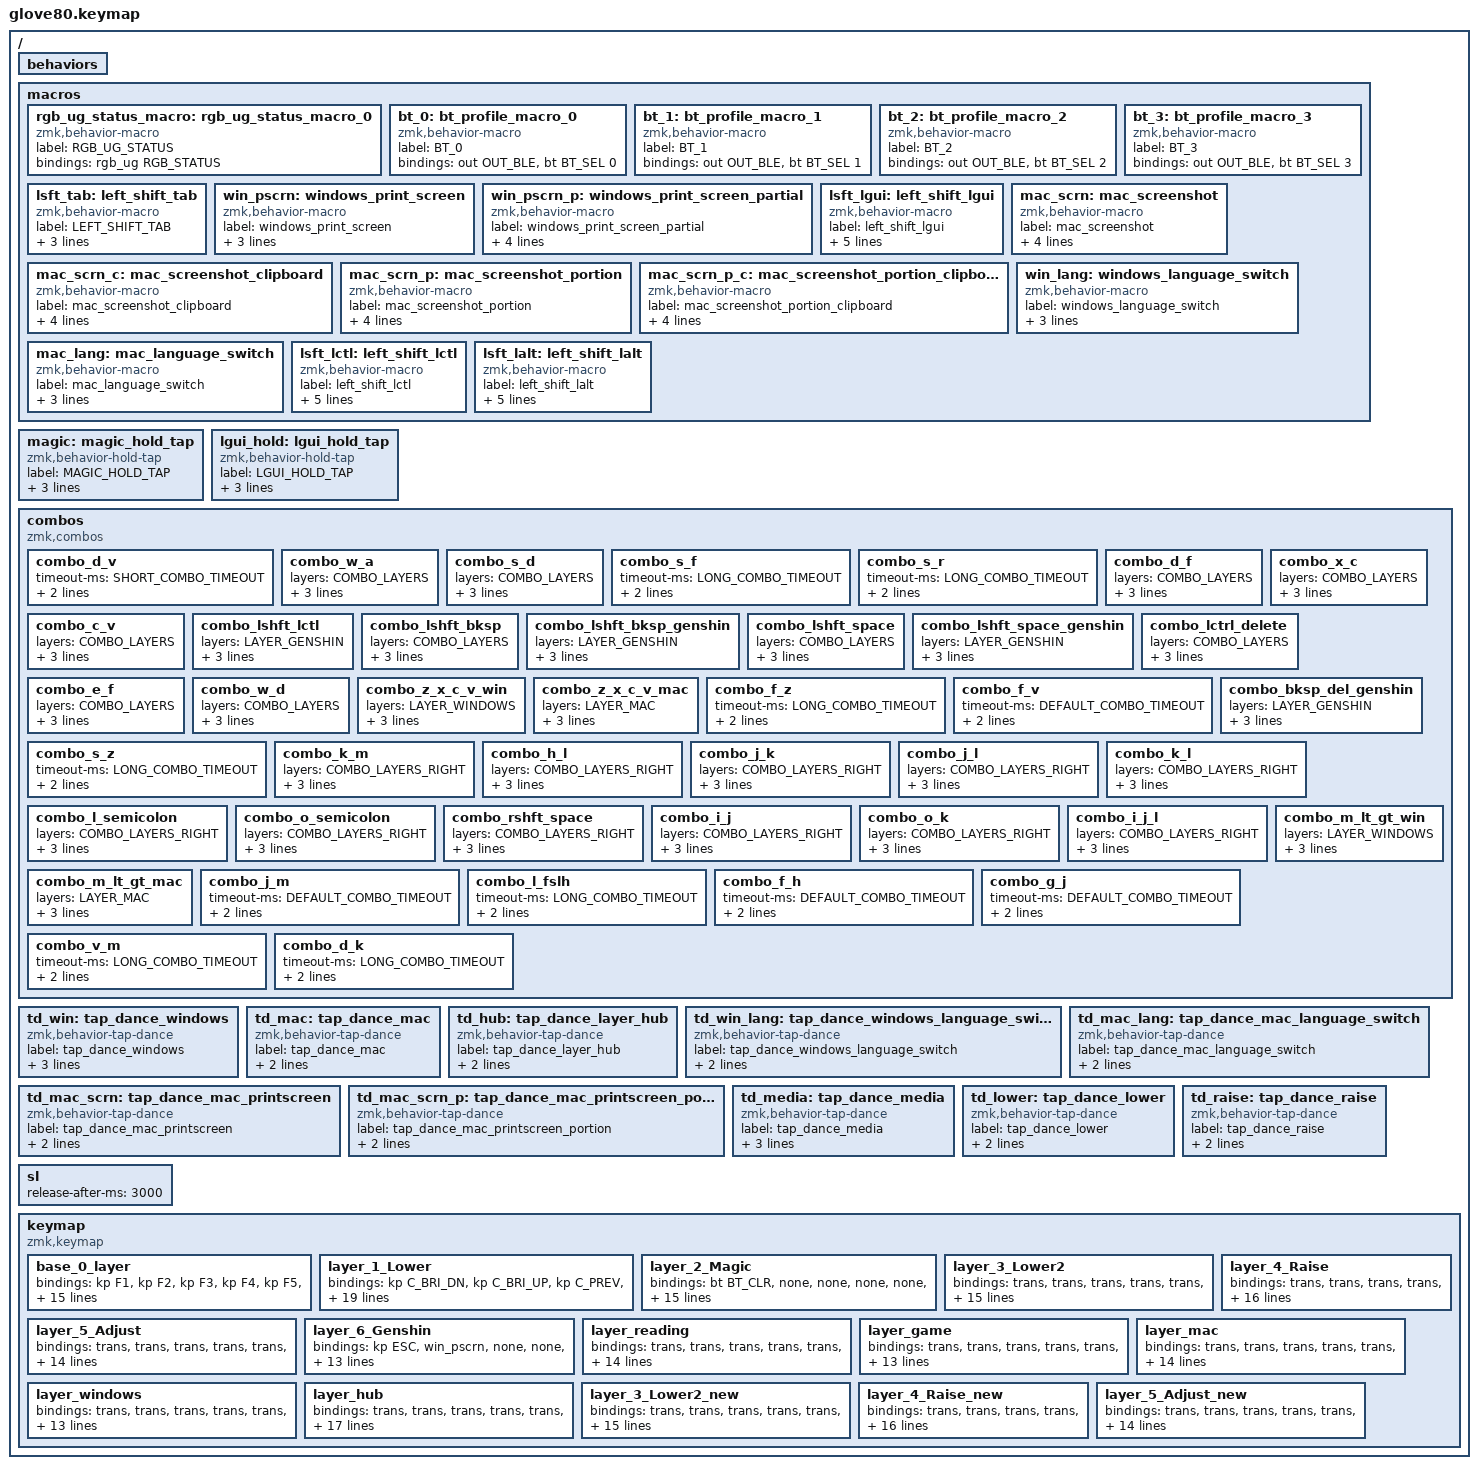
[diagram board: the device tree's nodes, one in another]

/*
 * Copyright (c) 2020 The ZMK Contributors
 * Copyright (c) 2022 Innaworks Development Limited, trading as MoErgo
 *
 * SPDX-License-Identifier: MIT
 */


/* THIS FILE WAS GENERATED BY GLOVE80 LAYOUT EDITOR
 *
 * This file was generated automatically. You may or may not want to
 * edit it directly.
 */

#include <behaviors.dtsi>
/* include all behaviour includes needed by system behaviors/macros */
#include <dt-bindings/zmk/outputs.h>

/* Include behaviour includes needed by key binds - automatically generated */
#include <dt-bindings/zmk/keys.h>
#include <dt-bindings/zmk/bt.h>
#include <dt-bindings/zmk/rgb.h>
#include <dt-bindings/zmk/outputs.h>

#define LAYER_DEFAULT 0
#define LAYER_LOWER_OLD 1
#define LAYER_MAGIC 2
//#define LAYER_LOWER 3
//#define LAYER_RAISE 4
//#define LAYER_ADJUST 5
#define LAYER_GENSHIN 6
#define LAYER_READING 7
#define LAYER_GAME 8
#define LAYER_MAC 9
#define LAYER_WINDOWS 10
#define LAYER_HUB 11
#define LAYER_LOWER 12
#define LAYER_RAISE 13
#define LAYER_ADJUST 14

#define COMBO_LAYERS LAYER_DEFAULT LAYER_READING LAYER_MAC LAYER_WINDOWS
#define COMBO_LAYERS_RIGHT COMBO_LAYERS LAYER_GENSHIN

#define MO_LOWER &mo LAYER_LOWER
#define MO_RAISE &mo LAYER_RAISE
#define MO_ADJUST &mo LAYER_ADJUST
#define MO_GENSHIN &mo LAYER_GENSHIN

#define TG_GENSHIN &tog LAYER_GENSHIN
#define TG_READING &tog LAYER_READING
#define TG_GAME &tog LAYER_GAME

#define TO_DEFAULT &to LAYER_DEFAULT
#define TO_GENSHIN &to LAYER_GENSHIN
#define TO_READING &to LAYER_READING
#define TO_GAME &to LAYER_GAME

#define MAGIC_DEFAULT &magic LAYER_MAGIC LAYER_DEFAULT 

#define SHORT_COMBO_TIMEOUT 10
#define DEFAULT_COMBO_TIMEOUT 30
#define LONG_COMBO_TIMEOUT 50

#define TAP_DANCE_TERM_SHORT 100
#define TAP_DANCE_TERM_DEFAULT 300
#define TAP_DANCE_TERM_LONG 400

/ {
    /* Glove80 system behavior & macros */
    behaviors {
        // For the "layer" key, it'd nice to be able to use it as either a shift or a toggle.
        // Configure it as a tap dance, so the first tap (or hold) is a &mo and the second tap is a &to
    };

    macros {
        rgb_ug_status_macro: rgb_ug_status_macro_0 {
            label = "RGB_UG_STATUS";
            compatible = "zmk,behavior-macro";
            #binding-cells = <0>;
            bindings
                = <&rgb_ug RGB_STATUS>;
        };
        bt_0: bt_profile_macro_0 {
            label = "BT_0";
            compatible = "zmk,behavior-macro";
            #binding-cells = <0>;
            bindings
                = <&out OUT_BLE>,
                  <&bt BT_SEL 0>;
        };
        bt_1: bt_profile_macro_1 {
            label = "BT_1";
            compatible = "zmk,behavior-macro";
            #binding-cells = <0>;
            bindings
                = <&out OUT_BLE>,
                  <&bt BT_SEL 1>;
        };
        bt_2: bt_profile_macro_2 {
            label = "BT_2";
            compatible = "zmk,behavior-macro";
            #binding-cells = <0>;
            bindings
                = <&out OUT_BLE>,
                  <&bt BT_SEL 2>;
        };
        bt_3: bt_profile_macro_3 {
            label = "BT_3";
            compatible = "zmk,behavior-macro";
            #binding-cells = <0>;
            bindings
                = <&out OUT_BLE>,
                  <&bt BT_SEL 3>;
        };
    };

    magic: magic_hold_tap {
        compatible = "zmk,behavior-hold-tap";
        label = "MAGIC_HOLD_TAP";
        #binding-cells = <2>;
        flavor = "tap-preferred";
        tapping-term-ms = <200>;
        bindings = <&mo>, <&rgb_ug_status_macro>;
    }; 

    // TODO: work on how to get this going
    lgui_hold: lgui_hold_tap {
        compatible = "zmk,behavior-hold-tap";
        label = "LGUI_HOLD_TAP";
        #binding-cells = <2>;
        flavor = "balanced";
        tapping-term-ms = <0>;
        bindings = <&none>, <&kp>;
    }; 

    /* Main Layer Combos */
    combos {
        compatible = "zmk,combos";

        /* left hand */
        combo_d_v {
            timeout-ms = <SHORT_COMBO_TIMEOUT>;
            key-positions = <37 50>;
            bindings = <&td_lower>;
        };
        combo_w_a {
            layers = <COMBO_LAYERS>;
            timeout-ms = <LONG_COMBO_TIMEOUT>;
            key-positions = <24 35>;
            bindings = <&kp ESC>;
        };
        combo_s_d {
            layers = <COMBO_LAYERS>;
            timeout-ms = <LONG_COMBO_TIMEOUT>;
            key-positions = <36 37>;
            bindings = <&kp LGUI>;
        };
        combo_s_f {
            timeout-ms = <LONG_COMBO_TIMEOUT>;
            key-positions = <36 38>;
            bindings = <&kp TAB>;
        };
        combo_s_r {
            timeout-ms = <LONG_COMBO_TIMEOUT>;
            key-positions = <36 26>;
            bindings = <&lsft_tab>;
        };
        combo_d_f {
            layers = <COMBO_LAYERS>;
            timeout-ms = <DEFAULT_COMBO_TIMEOUT>;
            key-positions = <37 38>;
            bindings = <&kp LCTL>;
        };
        combo_x_c {
            layers = <COMBO_LAYERS>;
            timeout-ms = <DEFAULT_COMBO_TIMEOUT>;
            key-positions = <48 49>;
            bindings = <&kp BACKSPACE>;
        };
        combo_c_v {
            layers = <COMBO_LAYERS>;
            timeout-ms = <30>;
            key-positions = <49 50>;
            bindings = <&kp ENTER>;
        };
        combo_lshft_lctl {
            layers = <LAYER_GENSHIN>;
            timeout-ms = <DEFAULT_COMBO_TIMEOUT>;
            key-positions = <52 53>;
            bindings = <&kp M>;
        };
        combo_lshft_bksp {
            layers = <COMBO_LAYERS>;
            timeout-ms = <DEFAULT_COMBO_TIMEOUT>;
            key-positions = <52 69>;
            bindings = <&kp LGUI>;
        };
        combo_lshft_bksp_genshin {
            layers = <LAYER_GENSHIN>;
            timeout-ms = <DEFAULT_COMBO_TIMEOUT>;
            key-positions = <52 69>;
            bindings = <&kp LALT>;
        };
        combo_lshft_space {
            layers = <COMBO_LAYERS>;
            timeout-ms = <DEFAULT_COMBO_TIMEOUT>;
            key-positions = <52 70>;
            bindings = <&lsft_lgui>;
        };
        combo_lshft_space_genshin {
            layers = <LAYER_GENSHIN>;
            timeout-ms = <DEFAULT_COMBO_TIMEOUT>;
            key-positions = <52 70>;
            bindings = <&kp J>;
        };
        combo_lctrl_delete {
            layers = <COMBO_LAYERS>;
            timeout-ms = <DEFAULT_COMBO_TIMEOUT>;
            key-positions = <53 70>;
            bindings = <&kp LALT>;
        };
        combo_e_f {
            layers = <COMBO_LAYERS>;
            timeout-ms = <DEFAULT_COMBO_TIMEOUT>;
            key-positions = <25 38>;
            bindings = <&lsft_lctl>;
        };
        combo_w_d {
            layers = <COMBO_LAYERS>;
            timeout-ms = <DEFAULT_COMBO_TIMEOUT>;
            key-positions = <24 37>;
            bindings = <&lsft_lgui>;
        };
        // this doesn't work for some reason
        /*
        combo_e_s_f {
            layers = <COMBO_LAYERS>;
            timeout-ms = <30>;
            key-positions = <25 36 38>;
            bindings = <&lsft_lalt>;
        };
        */
        combo_z_x_c_v_win {
            layers = <LAYER_WINDOWS>;
            timeout-ms = <LONG_COMBO_TIMEOUT>;
            key-positions = <47 48 49 50>;
            bindings = <&win_lang>;
        };
        combo_z_x_c_v_mac {
            layers = <LAYER_MAC>;
            timeout-ms = <LONG_COMBO_TIMEOUT>;
            key-positions = <47 48 49 50>;
            bindings = <&mac_lang>;
        };
        combo_f_z {   
            timeout-ms = <LONG_COMBO_TIMEOUT>;
            key-positions = <38 47>;
            bindings = <&sl LAYER_DEFAULT>;
        };
        combo_f_v {
            timeout-ms = <DEFAULT_COMBO_TIMEOUT>;
            key-positions = <38 50>;
            bindings = <&sl LAYER_LOWER>;
        };
        combo_s_z {
            timeout-ms = <LONG_COMBO_TIMEOUT>;
            key-positions = <36 47>;
            bindings = <&sl LAYER_HUB>;
        };
        combo_bksp_del_genshin {
            layers = <LAYER_GENSHIN>;
            timeout-ms = <DEFAULT_COMBO_TIMEOUT>;
            key-positions = <69 70>;
            bindings = <&kp M>;
        };

        /* right hand */
        combo_k_m {
            layers = <COMBO_LAYERS_RIGHT>;
            timeout-ms = <SHORT_COMBO_TIMEOUT>;
            key-positions = <42 59>;
            bindings = <&td_raise>;
        };
        combo_h_l {
            layers = <COMBO_LAYERS_RIGHT>;
            timeout-ms = <LONG_COMBO_TIMEOUT>;
            key-positions = <40 43>;
            bindings = <&kp LSHFT>;
        };
        combo_j_k {
            layers = <COMBO_LAYERS_RIGHT>;
            timeout-ms = <30>;
            key-positions = <41 42>;
            bindings = <&kp RCTRL>;
        };
        combo_j_l {
            layers = <COMBO_LAYERS_RIGHT>;
            timeout-ms = <30>;
            key-positions = <41 43>;
            bindings = <&kp RALT>;
        };
        combo_k_l {
            layers = <COMBO_LAYERS_RIGHT>;
            timeout-ms = <30>;
            key-positions = <42 43>;
            bindings = <&kp RGUI>;
        };
        combo_l_semicolon {
            layers = <COMBO_LAYERS_RIGHT>;
            timeout-ms = <LONG_COMBO_TIMEOUT>;
            key-positions = <43 44>;
            bindings = <&kp BACKSPACE>;
        };
        combo_o_semicolon {
            layers = <COMBO_LAYERS_RIGHT>;
            timeout-ms = <LONG_COMBO_TIMEOUT>;
            key-positions = <31 44>;
            bindings = <&kp ENTER>;
        };
        combo_rshft_space {
            layers = <COMBO_LAYERS_RIGHT>;
            timeout-ms = <30>;
            key-positions = <57 74>;
            bindings = <&kp RGUI>;
        };
        combo_i_j {
            layers = <COMBO_LAYERS_RIGHT>;
            timeout-ms = <30>;
            key-positions = <30 41>;
            bindings = <&lsft_lctl>;
        };
        combo_o_k {
            layers = <COMBO_LAYERS_RIGHT>;
            timeout-ms = <30>;
            key-positions = <31 42>;
            bindings = <&lsft_lgui>;
        };
        combo_i_j_l {
            layers = <COMBO_LAYERS_RIGHT>;
            timeout-ms = <30>;
            key-positions = <30 41 43>;
            bindings = <&lsft_lalt>;
        };
        combo_m_lt_gt_win {
            layers = <LAYER_WINDOWS>;
            timeout-ms = <LONG_COMBO_TIMEOUT>;
            key-positions = <59 60 61>;
            bindings = <&win_lang>;
        };
        combo_m_lt_gt_mac {
            layers = <LAYER_MAC>;
            timeout-ms = <LONG_COMBO_TIMEOUT>;
            key-positions = <59 60 61>;
            bindings = <&mac_lang>;
        };
        combo_j_m {
            timeout-ms = <DEFAULT_COMBO_TIMEOUT>;
            key-positions = <41 59>;
            bindings = <&sl LAYER_RAISE>;
        };
        // this doesn't work for some reason
        combo_l_fslh {
            timeout-ms = <LONG_COMBO_TIMEOUT>;
            key-positions = <43 62>;
            bindings = <&sl LAYER_HUB>;
        };

        /* left and right */
        combo_f_h {
            timeout-ms = <DEFAULT_COMBO_TIMEOUT>;
            key-positions = <38 40>;
            bindings = <&sl LAYER_LOWER>;
        };
        combo_g_j {
            timeout-ms = <DEFAULT_COMBO_TIMEOUT>;
            key-positions = <39 41>;
            bindings = <&sl LAYER_RAISE>;
        };
        combo_v_m {
            timeout-ms = <LONG_COMBO_TIMEOUT>;
            key-positions = <50 59>;
            bindings = <&sl LAYER_ADJUST>;
        };
        combo_d_k {
            timeout-ms = <LONG_COMBO_TIMEOUT>;
            key-positions = <37 42>;
            bindings = <&sl LAYER_HUB>;
        };
    };

    /* Custom Macros */
    macros {
        lsft_tab: left_shift_tab {
            label = "LEFT_SHIFT_TAB";
            compatible = "zmk,behavior-macro";
            #binding-cells = <0>;
            wait-ms = <0>;
            tap-ms = <0>;
            bindings = <&kt LSHFT &kp TAB &kt LSHFT>;
        };
        win_pscrn: windows_print_screen {
            label = "windows_print_screen";
            compatible = "zmk,behavior-macro";
            #binding-cells = <0>;
            wait-ms = <0>;
            tap-ms = <0>;
            bindings = <&kt LGUI &kp PSCRN &kt LGUI>;
        };
        win_pscrn_p: windows_print_screen_partial {
            label = "windows_print_screen_partial";
            compatible = "zmk,behavior-macro";
            #binding-cells = <0>;
            wait-ms = <0>;
            tap-ms = <0>;
            bindings = <&kt LGUI &kt LSHFT &kp S &kt LSHFT &kt LGUI>;
        };
        lsft_lgui: left_shift_lgui {
            label = "left_shift_lgui";
            compatible = "zmk,behavior-macro";
            #binding-cells = <0>;
            wait-ms = <0>;
            tap-ms = <0>;
            bindings 
                = <&macro_press &kp LSHFT &kp LGUI>
                , <&macro_pause_for_release>
                , <&macro_release &kp LGUI &kp LSHFT>;
        };
        mac_scrn: mac_screenshot {
            label = "mac_screenshot";
            compatible = "zmk,behavior-macro";
            #binding-cells = <0>;
            wait-ms = <0>;
            tap-ms = <0>;
            bindings = <&kt LSHFT &kt LGUI &kp N3 &kt LGUI &kt LSHFT>;
        };
        mac_scrn_c: mac_screenshot_clipboard {
            label = "mac_screenshot_clipboard";
            compatible = "zmk,behavior-macro";
            #binding-cells = <0>;
            wait-ms = <0>;
            tap-ms = <0>;
            bindings = <&kt LSHFT &kt LGUI &kt LCTL &kp N3 &kt LCTL &kt LGUI &kt LSHFT>;
        };
        mac_scrn_p: mac_screenshot_portion {
            label = "mac_screenshot_portion";
            compatible = "zmk,behavior-macro";
            #binding-cells = <0>;
            wait-ms = <0>;
            tap-ms = <0>;
            bindings = <&kt LSHFT &kt LGUI &kp N4 &kt LGUI &kt LSHFT>;
        };
        mac_scrn_p_c: mac_screenshot_portion_clipboard {
            label = "mac_screenshot_portion_clipboard";
            compatible = "zmk,behavior-macro";
            #binding-cells = <0>;
            wait-ms = <0>;
            tap-ms = <0>;
            bindings = <&kt LSHFT &kt LGUI &kt LCTL &kp N4 &kt LCTL &kt LGUI &kt LSHFT>;
        };
        win_lang: windows_language_switch {
            label = "windows_language_switch";
            compatible = "zmk,behavior-macro";
            #binding-cells = <0>;
            wait-ms = <0>;
            tap-ms = <0>;
            bindings = <&kt LGUI &kp SPACE &kt LGUI>;
        };
        mac_lang: mac_language_switch {
            label = "mac_language_switch";
            compatible = "zmk,behavior-macro";
            #binding-cells = <0>;
            wait-ms = <0>;
            tap-ms = <0>;
            bindings = <&kt LCTRL &kp SPACE &kt LCTRL>;
        };
        lsft_lctl: left_shift_lctl {
            label = "left_shift_lctl";
            compatible = "zmk,behavior-macro";
            #binding-cells = <0>;
            wait-ms = <0>;
            tap-ms = <0>;
            bindings 
                = <&macro_press &kp LSHFT &kp LCTL>
                , <&macro_pause_for_release>
                , <&macro_release &kp LCTL &kp LSHFT>;
        };
        lsft_lalt: left_shift_lalt {
            label = "left_shift_lalt";
            compatible = "zmk,behavior-macro";
            #binding-cells = <0>;
            wait-ms = <0>;
            tap-ms = <0>;
            bindings 
                = <&macro_press &kp LSHFT &kp LALT>
                , <&macro_pause_for_release>
                , <&macro_release &kp LALT &kp LSHFT>;
        };
    };

    td_win: tap_dance_windows {
        compatible = "zmk,behavior-tap-dance";
        label = "tap_dance_windows";
        #binding-cells = <0>;
        tapping-term-ms = <TAP_DANCE_TERM_DEFAULT>;
        bindings = <&none>, <&sl LAYER_WINDOWS>, <&tog LAYER_WINDOWS>;
    };
    td_mac: tap_dance_mac {
        compatible = "zmk,behavior-tap-dance";
        label = "tap_dance_mac";
        #binding-cells = <0>;
        tapping-term-ms = <TAP_DANCE_TERM_DEFAULT>;
        bindings = <&none>, <&sl LAYER_MAC>, <&tog LAYER_MAC>;
    };
    td_hub: tap_dance_layer_hub {
        compatible = "zmk,behavior-tap-dance";
        label = "tap_dance_layer_hub";
        #binding-cells = <0>;
        tapping-term-ms = <TAP_DANCE_TERM_DEFAULT>;
        bindings = <&none>, <&sl LAYER_HUB>, <&to LAYER_DEFAULT>;
    };
    td_win_lang: tap_dance_windows_language_switch {
        compatible = "zmk,behavior-tap-dance";
        label = "tap_dance_windows_language_switch";
        #binding-cells = <0>;
        tapping-term-ms = <TAP_DANCE_TERM_DEFAULT>;
        bindings = <&kp LALT>, <&win_lang>;
    };
    td_mac_lang: tap_dance_mac_language_switch {
        compatible = "zmk,behavior-tap-dance";
        label = "tap_dance_mac_language_switch";
        #binding-cells = <0>;
        tapping-term-ms = <TAP_DANCE_TERM_DEFAULT>;
        bindings = <&kp LALT>, <&mac_lang>;
    };
    td_mac_scrn: tap_dance_mac_printscreen {
        compatible = "zmk,behavior-tap-dance";
        label = "tap_dance_mac_printscreen";
        #binding-cells = <0>;
        tapping-term-ms = <TAP_DANCE_TERM_DEFAULT>;
        bindings = <&mac_scrn>, <&mac_scrn_c>;
    };
    td_mac_scrn_p: tap_dance_mac_printscreen_portion {
        compatible = "zmk,behavior-tap-dance";
        label = "tap_dance_mac_printscreen_portion";
        #binding-cells = <0>;
        tapping-term-ms = <TAP_DANCE_TERM_DEFAULT>;
        bindings = <&mac_scrn_p>, <&mac_scrn_p_c>;
    };
    td_media: tap_dance_media {
        compatible = "zmk,behavior-tap-dance";
        label = "tap_dance_media";
        #binding-cells = <0>;
        tapping-term-ms = <TAP_DANCE_TERM_DEFAULT>;
        bindings = <&kp C_PLAY_PAUSE>, <&kp C_MUTE>, <&kp C_NEXT>, <&kp C_PREVIOUS>;
    };
    td_lower: tap_dance_lower {
        compatible = "zmk,behavior-tap-dance";
        label = "tap_dance_lower";
        #binding-cells = <0>;
        tapping-term-ms = <TAP_DANCE_TERM_SHORT>;
        bindings = <&mo LAYER_LOWER>, <&sl LAYER_LOWER>;
    };
    td_raise: tap_dance_raise {
        compatible = "zmk,behavior-tap-dance";
        label = "tap_dance_raise";
        #binding-cells = <0>;
        tapping-term-ms = <TAP_DANCE_TERM_SHORT>;
        bindings = <&mo LAYER_RAISE>, <&sl LAYER_RAISE>;
    };

    sl {
        release-after-ms = <3000>;
    };

    keymap {
        compatible = "zmk,keymap";

        base_0_layer {
            bindings = <
  &kp F1                           &kp F2   &kp F3    &kp F4     &kp F5                                                                                                 &kp C_VOL_DN    &kp C_VOL_UP    &td_media       &none           &win_pscrn
  &kp TILDE                        &kp N1   &kp N2    &kp N3     &kp N4  &kp N5                                                                                 &kp N6  &kp N7          &kp N8          &kp N9          &kp N0          &kp MINUS
  &kp TAB                          &kp Q    &kp W     &kp E      &kp R   &kp T                                                                                  &kp Y   &kp U           &kp I           &kp O           &kp P           &kp PIPE
  &kp ESC                          &kp A    &kp S     &kp D      &kp F   &kp G                                                                                  &kp H   &kp J           &kp K           &kp L           &kp SEMI        &kp SINGLE_QUOTE
  &kp GRAVE                        &kp Z    &kp X     &kp C      &kp V   &kp B  &kp LSHFT        &kp LCTRL    MAGIC_DEFAULT &kp LGUI &kp RCTRL  &kp RSHFT       &kp N   &kp M           &kp COMMA       &kp DOT         &kp SLASH       &kp BSLH
  &td_hub                          &td_win  &td_mac   &kp ESC    &kp LALT       MO_LOWER         &kp SPACE    &kp LALT      &kp RALT &kp BSPC   MO_RAISE                &kp LEFT        &kp DOWN        &kp UP          &kp RIGHT      &kp PG_DN
            >;
        };

        layer_1_Lower {
            bindings = <
 &kp C_BRI_DN                            &kp C_BRI_UP      &kp C_PREV      &kp C_NEXT         &kp C_PP                                                                                    &kp C_MUTE  &kp C_VOL_DN  &kp C_VOL_UP            &none  &kp PAUSE_BREAK
       &trans                            &none           &none           &none            &none   &kp HOME                                                   &kp LEFT_PARENTHESIS  &kp KP_NUM  &kp KP_EQUAL  &kp KP_SLASH  &kp KP_MULTIPLY  &kp PRINTSCREEN
       &trans                            &none           &none    &kp UP_ARROW            &none    &kp END                                                  &kp RIGHT_PARENTHESIS   &kp KP_N7     &kp KP_N8     &kp KP_N9     &kp KP_MINUS   &kp SCROLLLOCK
       &trans                            &none  &kp LEFT_ARROW  &kp DOWN_ARROW  &kp RIGHT_ARROW  &kp PG_UP                                                            &kp PERCENT   &kp KP_N4     &kp KP_N5     &kp KP_N6      &kp KP_PLUS            &none
       &trans                            &kp K_APP           &none         &kp F11          &kp F12  &kp PG_DN  &trans  &trans   &to 0  &trans  &trans  &trans              &kp COMMA   &kp KP_N1     &kp KP_N2     &kp KP_N3     &kp KP_ENTER           &trans
   &magic LAYER_MAGIC LAYER_DEFAULT      &kp CAPS         &kp INS         &kp F11          &kp F12             &trans  &trans  &trans  &trans  &trans  &trans                          &kp KP_N0     &kp KP_N0    &kp KP_DOT     &kp KP_ENTER           &trans
            >;
        };

        layer_2_Magic {
            bindings = <
  &bt BT_CLR            &none            &none            &none            &none                                                                          &none   &none   &none   &none  &bt BT_CLR_ALL
       &none            &none            &none            &none            &none            &none                                                         &none   &none   &none   &none   &none           &none
      &trans  &rgb_ug RGB_SPI  &rgb_ug RGB_SAI  &rgb_ug RGB_HUI  &rgb_ug RGB_BRI  &rgb_ug RGB_TOG                                                         &none   &none   &none   &none   &none           &none
 &bootloader  &rgb_ug RGB_SPD  &rgb_ug RGB_SAD  &rgb_ug RGB_HUD  &rgb_ug RGB_BRD  &rgb_ug RGB_EFF                                                         &none   &none   &none   &none   &none     &bootloader
      &reset            &none            &none            &none            &none            &none   &bt_2   &bt_3         &none   &none   &none   &none   &none   &none   &none   &none   &none          &reset
       &none            &none            &none            &none            &none                    &bt_0   &bt_1  &out OUT_USB   &none   &none   &none           &none   &none   &none   &none           &none
            >;
        };

        /*
        layer_template {
            bindings = <
      &trans            &trans            &trans            &trans            &trans                                                                                                                                &trans           &trans          &trans           &trans            &trans
      &trans            &trans            &trans            &trans            &trans            &trans                                                                                              &trans          &trans           &trans          &trans           &trans            &trans
      &trans            &trans            &trans            &trans            &trans            &trans                                                                                              &trans          &trans           &trans          &trans           &trans            &trans
      &trans            &trans            &trans            &trans            &trans            &trans                                                                                              &trans          &trans           &trans          &trans           &trans            &trans
      &trans            &trans            &trans            &trans            &trans            &trans        &trans        &trans         &trans        &trans         &trans        &trans        &trans          &trans           &trans          &trans           &trans            &trans
      &trans            &trans            &trans            &trans            &trans                          &trans        &trans         &trans        &trans         &trans        &trans                        &trans           &trans          &trans           &trans            &trans
            >;
        };
        */
        
        layer_3_Lower2 {
            bindings = <
      &trans            &trans            &trans            &trans            &trans                                                                                                                                &trans           &trans          &trans           &trans            &trans
      &trans            &trans            &trans            &trans            &trans            &trans                                                                                              &trans          &trans           &trans          &trans           &trans            &trans
      &kp F1            &kp F2            &kp F3            &kp F4            &kp F5            &kp F6                                                                                              &kp F7          &kp F8           &kp F9          &kp F10          &kp F11           &kp F12
      &kp GRAVE         &kp EXCL          &kp AT            &kp HASH          &kp DOLLAR        &kp PERCENT                                                                                         &kp CARET       &kp AMPS         &kp ASTERISK    &kp LPAR         &kp RPAR          &trans
      &trans            &trans            &trans            &trans            &trans            &trans        &trans        &trans         &trans        &trans         &trans        &trans        &trans          &kp UNDERSCORE   &kp PLUS        &kp LEFT_BRACE   &kp RIGHT_BRACE   &trans
      &trans            &trans            &trans            &trans            &trans                          &trans        &trans         &trans        &trans         &trans        MO_ADJUST                     &trans           &trans          &trans           &trans            &trans
            >;
        };
        
        layer_4_Raise {
            bindings = <
      &trans            &trans            &trans            &trans            &trans                                                                                                                                TG_GENSHIN       TG_READING      TG_GAME          &trans            &trans
      &trans            &trans            &trans            &trans            &trans            &trans                                                                                              &trans          &trans           &trans          &trans           &trans            &kp C_PP
      &kp GRAVE         &kp NUM_1         &kp NUM_2         &kp NUM_3         &kp NUM_4         &kp NUM_5                                                                                           &kp NUM_6       &kp NUM_7        &kp NUM_8       &kp NUM_9        &kp NUM_0         &kp C_VOL_UP
      &kp F1            &kp F2            &kp F3            &kp F4            &kp F5            &kp F6                                                                                              &kp LEFT        &kp DOWN         &kp UP          &kp RIGHT        &trans            &kp C_VOL_DN
      &kp F7            &kp F8            &kp F9            &kp F10           &kp F11           &kp F12       &trans        &trans         &trans        &trans         &trans        &trans        &kp PLUS        &kp MINUS        &kp EQUAL       &kp LEFT_BRACKET &kp RIGHT_BRACKET &kp TILDE
      &trans            &trans            &trans            &trans            &trans                          MO_ADJUST     &trans         &trans        &trans         &trans        &trans                        &trans           &trans          &trans           &trans            &trans
            >;
        };
        
        layer_5_Adjust {
            bindings = <
      &trans            &trans            &trans            &trans            &trans                                                                                                                                  &trans           &trans          &trans           &trans            &trans
      &trans            &trans            &trans            &trans            &trans            &trans                                                                                                &trans          &trans           &trans          &trans           &trans            &trans
      &trans            &trans            &kp INSERT        &kp HOME          &kp PAGE_UP       &trans                                                                                                &trans          &kp KP_N7        &kp KP_N8       &kp KP_N9        &trans            &trans
      &trans            &trans            &kp DELETE        &kp END           &kp PAGE_DOWN     &trans                                                                                                &kp KP_DOT      &kp KP_N4        &kp KP_N5       &kp KP_N6        &trans            &trans
      &trans            &trans            &trans            &trans            &trans            &trans        &trans         &trans          &trans        &trans         &trans        &trans        &kp KP_N0       &kp KP_N1        &kp KP_N2       &kp KP_N3        &trans            &trans
      &trans            &trans            &trans            &trans            &trans                          &trans         &trans          &trans        &trans         &trans        &trans                        &trans           &trans          &trans           &trans            &trans
            >;
        };

        layer_6_Genshin {
            bindings = <
      &kp ESC           &win_pscrn        &none             &none             &kp N5                                                                                                                                &trans           &trans          &trans           &trans            &trans 
      &kp ESC           &kp N1            &kp N2            &kp N3            &kp N4            &kp N5                                                                                              &trans          &trans           &trans          &trans           &trans            &trans
      &kp TAB           &kp Q             &kp W             &kp E             &kp R             &kp T                                                                                               &trans          &trans           &trans          &trans           &trans            &trans
      &kp LALT          &kp A             &kp S             &kp D             &kp F             &kp G                                                                                               &trans          &trans           &trans          &trans           &trans            &trans
      &kp LSHFT         &kp Z             &kp X             &kp C             &kp V             &kp B         &kp ESC        &trans          TG_GENSHIN    &trans         &trans        &trans      &trans          &trans           &trans          &trans           &trans            &trans
      &trans            &none             &kp J             &kp M             &kp LCTL                        &kp SPACE      MO_LOWER        &kp LCTL      &trans         &trans        &trans                      &trans           &trans          &trans           &trans            &trans
            >;
        };

        layer_reading {
            bindings = <
      &trans            &trans            &trans            &trans            &trans                                                                                                                                &trans           &trans          &trans           &trans            &trans
      &trans            &trans            &kp HOME          &kp END           &trans            &trans                                                                                              &trans          &trans           &trans          &trans           &trans            &trans
      &trans            &trans            &trans            &kp UP            &trans            &kp PAGE_UP                                                                                         &trans          &trans           &trans          &trans           &trans            &trans
      &trans            &trans            &kp LEFT          &kp DOWN          &kp RIGHT         &kp PAGE_DOWN                                                                                       &trans          &trans           &trans          &trans           &trans            &trans
      &trans            &trans            &trans            &trans            &trans            &trans        &trans        &trans         TG_READING    &trans         &trans        &trans        &trans          &trans           &trans          &trans           &trans            &trans
      &trans            &trans            &trans            &trans            &kp ESC                         &kp ENTER     &trans         &trans        &trans         &trans        &trans                        &trans           &trans          &trans           &trans            &trans
            >;
        };
        
        layer_game {
            bindings = <
      &trans            &trans            &trans            &trans            &trans                                                                                                                                &trans           &trans          &trans           &trans            &trans
      &trans            &trans            &trans            &trans            &trans            &trans                                                                                              &trans          &trans           &trans          &trans           &trans            &trans
      &trans            &trans            &trans            &trans            &trans            &trans                                                                                              &trans          &trans           &trans          &trans           &trans            &trans
      &trans            &trans            &trans            &trans            &trans            &trans                                                                                              &trans          &trans           &trans          &trans           &trans            &trans
      &trans            &trans            &trans            &trans            &trans            &trans        &trans        &trans         TG_GAME       &trans         &trans        &trans        &trans          &trans           &trans          &trans           &trans            &trans
      &trans            &trans            &trans            &trans            &trans                          &kp ENTER     &trans         &trans        &trans         &trans        &trans                        &trans           &trans          &trans           &trans            &trans
            >;
        };
        
        layer_mac {
            bindings = <
      &trans            &trans            &trans            &trans            &trans                                                                                                                                &trans           &trans          &trans           &td_mac_scrn_p    &td_mac_scrn
      &trans            &trans            &trans            &trans            &trans            &trans                                                                                              &trans          &trans           &trans          &trans           &trans            &trans
      &trans            &trans            &trans            &trans            &trans            &trans                                                                                              &trans          &trans           &trans          &trans           &trans            &trans
      &trans            &trans            &trans            &trans            &trans            &trans                                                                                              &trans          &trans           &trans          &trans           &trans            &trans
      &trans            &trans            &trans            &trans            &trans            &trans        &trans        &trans         &trans        &trans         &trans        &trans        &trans          &trans           &trans          &trans           &trans            &trans
      &trans            &trans            &trans            &trans            &td_mac_lang                    &trans        &trans         &trans        &trans         &trans        &trans                        &trans           &trans          &trans           &trans            &trans
            >;
        };
        
        layer_windows {
            bindings = <
      &trans            &trans            &trans            &trans            &trans                                                                                                                                &trans           &trans          &trans           &win_pscrn_p      &win_pscrn
      &trans            &trans            &trans            &trans            &trans            &trans                                                                                              &trans          &trans           &trans          &trans           &trans            &trans
      &trans            &trans            &trans            &trans            &trans            &trans                                                                                              &trans          &trans           &trans          &trans           &trans            &trans
      &trans            &trans            &trans            &trans            &trans            &trans                                                                                              &trans          &trans           &trans          &trans           &trans            &trans
      &trans            &trans            &trans            &trans            &trans            &trans        &trans        &trans         &trans        &trans         &trans        &trans        &trans          &trans           &trans          &trans           &trans            &trans
      &trans            &trans            &trans            &trans            &td_win_lang                    &trans        &trans         &trans        &trans         &trans        &trans                        &trans           &trans          &trans           &trans            &trans
            >;
        };
        
        layer_hub {
            bindings = <
      &trans            &trans             &trans             &trans            &trans                                                                                                                                   &trans             &trans            &trans           &trans            &trans
      &trans            &to LAYER_GENSHIN  &to LAYER_READING  &to LAYER_GAME    &trans               &trans                                                                                              &trans          &trans             &trans            &trans           &trans            &trans
      &trans            &trans             &to LAYER_GENSHIN  &to LAYER_READING &to LAYER_GAME       &trans                                                                                              &trans          &to LAYER_GENSHIN  &to LAYER_READING &to LAYER_GAME   &trans            &trans
      &trans            &trans             TO_DEFAULT         TO_DEFAULT        &trans               &trans                                                                                              &trans          &trans             TO_DEFAULT        TO_DEFAULT       &trans            &trans
      &trans            &trans             &trans             &trans            &trans               &trans        &trans        &trans         &trans        &trans         &trans        &trans        &trans          &trans             &trans            &trans           &trans            &trans
      &trans            &trans             &trans             &trans            &trans                             TO_DEFAULT    &trans         &trans        &trans         &trans        TO_DEFAULT                    &trans             &trans            &trans           &trans            &trans
            >;
        };
        
        layer_3_Lower2_new {
            bindings = <
      &trans            &trans            &trans            &trans            &trans                                                                                                                                &trans           &trans          &trans           &trans            &trans
      &trans            &trans            &trans            &trans            &trans            &trans                                                                                              &trans          &trans           &trans          &trans           &trans            &trans
      &kp F1            &kp F2            &kp F3            &kp F4            &kp F5            &kp F6                                                                                              &kp F7          &kp F8           &kp F9          &kp F10          &kp F11           &kp F12
      &kp GRAVE         &kp EXCL          &kp AT            &kp HASH          &kp DOLLAR        &kp PERCENT                                                                                         &kp CARET       &kp AMPS         &kp ASTERISK    &kp LPAR         &kp RPAR          &trans
      &trans            &trans            &trans            &trans            &trans            &trans        &trans        &trans         &trans        &trans         &trans        &trans        &trans          &kp UNDERSCORE   &kp PLUS        &kp LEFT_BRACE   &kp RIGHT_BRACE   &trans
      &trans            &trans            &trans            &trans            &trans                          &trans        &trans         &trans        &trans         &trans        MO_ADJUST                     &trans           &trans          &trans           &trans            &trans
            >;
        };
        
        layer_4_Raise_new {
            bindings = <
      &trans            &trans            &trans            &trans            &trans                                                                                                                                TG_GENSHIN       TG_READING      TG_GAME          &trans            &trans
      &trans            &trans            &trans            &trans            &trans            &trans                                                                                              &trans          &trans           &trans          &trans           &trans            &kp C_PP
      &kp GRAVE         &kp NUM_1         &kp NUM_2         &kp NUM_3         &kp NUM_4         &kp NUM_5                                                                                           &kp NUM_6       &kp NUM_7        &kp NUM_8       &kp NUM_9        &kp NUM_0         &kp C_VOL_UP
      &kp F1            &kp F2            &kp F3            &kp F4            &kp F5            &kp F6                                                                                              &kp LEFT        &kp DOWN         &kp UP          &kp RIGHT        &trans            &kp C_VOL_DN
      &kp F7            &kp F8            &kp F9            &kp F10           &kp F11           &kp F12       &trans        &trans         &trans        &trans         &trans        &trans        &kp PLUS        &kp MINUS        &kp EQUAL       &kp LEFT_BRACKET &kp RIGHT_BRACKET &kp TILDE
      &trans            &trans            &trans            &trans            &trans                          MO_ADJUST     &trans         &trans        &trans         &trans        &trans                        &trans           &trans          &trans           &trans            &trans
            >;
        };
        
        layer_5_Adjust_new {
            bindings = <
      &trans            &trans            &trans            &trans            &trans                                                                                                                                  &trans           &trans          &trans           &trans            &trans
      &trans            &trans            &trans            &trans            &trans            &trans                                                                                                &trans          &trans           &trans          &trans           &trans            &trans
      &trans            &trans            &kp INSERT        &kp HOME          &kp PAGE_UP       &trans                                                                                                &trans          &kp KP_N7        &kp KP_N8       &kp KP_N9        &trans            &trans
      &trans            &trans            &kp DELETE        &kp END           &kp PAGE_DOWN     &trans                                                                                                &kp KP_DOT      &kp KP_N4        &kp KP_N5       &kp KP_N6        &trans            &trans
      &trans            &trans            &trans            &trans            &trans            &trans        &trans         &trans          &trans        &trans         &trans        &trans        &kp KP_N0       &kp KP_N1        &kp KP_N2       &kp KP_N3        &trans            &trans
      &trans            &trans            &trans            &trans            &trans                          &trans         &trans          &trans        &trans         &trans        &trans                        &trans           &trans          &trans           &trans            &trans
            >;
        };
    };
};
